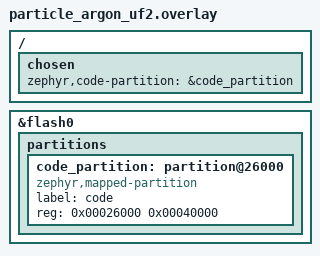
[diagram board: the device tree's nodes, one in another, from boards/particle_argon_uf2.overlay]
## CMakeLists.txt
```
cmake_minimum_required(VERSION 3.20.0)
find_package(Zephyr REQUIRED HINTS $ENV{ZEPHYR_BASE})
project(blank_app)

target_sources(app PRIVATE src/main.c)
```

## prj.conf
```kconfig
# blank_app - the minimal starting point for your own firmware on either
# board, with no dependency on Arduino IDE, no dependency on the mesh
# project, and no dependency on the ESP32 passthrough. This is what "raw
# Zephyr on this hardware" looks like at its smallest - copy this folder
# to start a real project.

CONFIG_GPIO=y

# --- Native USB-CDC console --------------------------------------------
# Same pattern as xenon_sensor/argon_gateway (see their own prj.conf/
# overlay comments for the full writeup): both boards' upstream devicetree
# defaults zephyr,console to &uart0, a header pin nothing is physically
# wired to on this project's bench setup - repointed to USB-CDC-ACM here
# via each board's own overlay instead, so printk/LOG output reaches a
# host over the same USB cable used for flashing and power.
CONFIG_LOG=y
CONFIG_CONSOLE=y
CONFIG_UART_CONSOLE=y
CONFIG_STDOUT_CONSOLE=y
CONFIG_USB_DEVICE_STACK_NEXT=y
CONFIG_CDC_ACM_SERIAL_INITIALIZE_AT_BOOT=y
CONFIG_CDC_ACM_SERIAL_PRODUCT_STRING="Blank App Console"
```

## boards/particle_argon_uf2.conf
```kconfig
# blank_app EXTRA Kconfig fragment - UF2/bootloader-safe build variant.
#
# Companion to boards/particle_argon_uf2.overlay, applied together via
# -DEXTRA_CONF_FILE alongside -DEXTRA_DTC_OVERLAY_FILE. The devicetree
# overlay alone is NOT enough to relocate the link address: Zephyr only
# links the app into its devicetree zephyr,code-partition when
# CONFIG_USE_DT_CODE_PARTITION is on, and that Kconfig option defaults to
# off on this SoC (confirmed by inspecting the plain overlay-only build's
# own .config and generated zephyr.hex, which still start at 0x0 even
# with the code_partition node present - and by reproducing the same
# default-off behavior on Zephyr's own upstream reference board for this
# exact scenario, adafruit_feather_nrf52840/nrf52840/uf2). Without this,
# the overlay's new partition would sit unused in the devicetree and the
# build would silently keep linking at 0x0 - exactly the failure mode
# Bug 1 is about, just moved one layer deeper.
CONFIG_USE_DT_CODE_PARTITION=y
```

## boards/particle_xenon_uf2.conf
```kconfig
# blank_app EXTRA Kconfig fragment - UF2/bootloader-safe build variant.
#
# Companion to boards/particle_xenon_uf2.overlay, applied together via
# -DEXTRA_CONF_FILE alongside -DEXTRA_DTC_OVERLAY_FILE. The devicetree
# overlay alone is NOT enough to relocate the link address: Zephyr only
# links the app into its devicetree zephyr,code-partition when
# CONFIG_USE_DT_CODE_PARTITION is on, and that Kconfig option defaults to
# off on this SoC (confirmed by inspecting the plain overlay-only build's
# own .config and generated zephyr.hex, which still start at 0x0 even
# with the code_partition node present - and by reproducing the same
# default-off behavior on Zephyr's own upstream reference board for this
# exact scenario, adafruit_feather_nrf52840/nrf52840/uf2). Without this,
# the overlay's new partition would sit unused in the devicetree and the
# build would silently keep linking at 0x0 - exactly the failure mode
# Bug 1 is about, just moved one layer deeper.
CONFIG_USE_DT_CODE_PARTITION=y
```

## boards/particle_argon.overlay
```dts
/*
 * blank_app board overlay - particle_argon
 *
 * Repoints the console to USB-CDC-ACM - same fix already applied and
 * verified on real hardware for argon_gateway/xenon_sensor/esp32_passthrough
 * (see their own overlays). Nothing else needs adding: led1 (the red
 * status LED) is already declared as a devicetree alias in the shared
 * mesh_feather.dtsi this board includes.
 */

/ {
	chosen {
		zephyr,console = &cdc_acm_uart0;
	};
};

&zephyr_udc0 {
	cdc_acm_uart0: cdc_acm_uart0 {
		compatible = "zephyr,cdc-acm-uart";
	};
};
```

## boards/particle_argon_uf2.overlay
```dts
/*
 * blank_app EXTRA overlay - UF2/bootloader-safe build variant.
 *
 * Applied ON TOP OF the board's own particle_argon.overlay /
 * particle_xenon.overlay (via -DEXTRA_DTC_OVERLAY_FILE), producing a
 * SEPARATE build meant for installing via UF2 drag-and-drop onto a board
 * that already has Adafruit's nRF52 bootloader + SoftDevice S140 - NOT
 * for direct SWD mass-erase flashing (that's what the plain per-board
 * overlay, unmodified by this file, remains for).
 *
 * The default board devicetree links application code at flash address
 * 0x0 - correct for a bare chip with no bootloader, wrong once a
 * bootloader/SoftDevice already occupies that address range: writing a
 * 0x0-linked image through UF2 corrupts the bootloader's own territory
 * and nothing valid ever boots (confirmed on real hardware this session -
 * see this project's SDD ledger, Argon UF2 round-trip task).
 *
 * 0x26000 is the same flash offset this project's own Arduino-sketch
 * SWD-flashing tooling already relies on for code living above
 * SoftDevice S140 and below the bootloader. 0x40000 (256KB) is a
 * deliberately conservative partition size for a small template app -
 * far below any real bootloader location near the top of the 1MB flash.
 *
 * Partition-conflict note: the board's default devicetree (via
 * mesh_feather.dtsi -> <nordic/nrf52840_partition.dtsi>) already defines
 * slot0_partition spanning 0xc000-0x82000, which fully contains our
 * 0x26000-0x66000 window - a real, physically-overlapping conflict, not
 * a hypothetical one. It's an MCUboot slot this app has no use for (this
 * app doesn't use MCUboot), so it's deleted below to clear the range.
 * Zephyr's own upstream partition layout for this exact scenario -
 * dts/vendor/nordic/nrf52840_partition_uf2_sdv6.dtsi, used by the real
 * Adafruit Feather nRF52840 UF2 board target - uses the same
 * "zephyr,mapped-partition" compatible for its application partition,
 * so that's what's used here too rather than the older
 * "fixed-partitions" style (which the board's existing partitions node
 * doesn't use in the first place).
 */

/delete-node/ &slot0_partition;

&flash0 {
	partitions {
		code_partition: partition@26000 {
			compatible = "zephyr,mapped-partition";
			label = "code";
			reg = <0x00026000 0x00040000>;
		};
	};
};

/ {
	chosen {
		zephyr,code-partition = &code_partition;
	};
};
```

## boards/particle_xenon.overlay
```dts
/*
 * blank_app board overlay - particle_xenon
 *
 * Same USB-CDC-ACM console fix as boards/particle_argon.overlay - see
 * that file's comment for the full writeup.
 */

/ {
	chosen {
		zephyr,console = &cdc_acm_uart0;
	};
};

&zephyr_udc0 {
	cdc_acm_uart0: cdc_acm_uart0 {
		compatible = "zephyr,cdc-acm-uart";
	};
};
```

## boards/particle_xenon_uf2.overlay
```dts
/*
 * blank_app EXTRA overlay - UF2/bootloader-safe build variant.
 *
 * Applied ON TOP OF the board's own particle_xenon.overlay (via
 * -DEXTRA_DTC_OVERLAY_FILE), producing a
 * SEPARATE build meant for installing via UF2 drag-and-drop onto a board
 * that already has Adafruit's nRF52 bootloader + SoftDevice S140 - NOT
 * for direct SWD mass-erase flashing (that's what the plain per-board
 * overlay, unmodified by this file, remains for).
 *
 * The default board devicetree links application code at flash address
 * 0x0 - correct for a bare chip with no bootloader, wrong once a
 * bootloader/SoftDevice already occupies that address range: writing a
 * 0x0-linked image through UF2 corrupts the bootloader's own territory
 * and nothing valid ever boots (confirmed on real hardware this session -
 * see this project's SDD ledger, Argon UF2 round-trip task).
 *
 * 0x26000 is the same flash offset this project's own Arduino-sketch
 * SWD-flashing tooling already relies on for code living above
 * SoftDevice S140 and below the bootloader. 0x40000 (256KB) is a
 * deliberately conservative partition size for a small template app -
 * far below any real bootloader location near the top of the 1MB flash.
 *
 * Partition-conflict note: the board's default devicetree (via
 * mesh_feather.dtsi -> <nordic/nrf52840_partition.dtsi>) already defines
 * slot0_partition spanning 0xc000-0x82000, which fully contains our
 * 0x26000-0x66000 window - a real, physically-overlapping conflict, not
 * a hypothetical one. It's an MCUboot slot this app has no use for (this
 * app doesn't use MCUboot), so it's deleted below to clear the range.
 * Zephyr's own upstream partition layout for this exact scenario -
 * dts/vendor/nordic/nrf52840_partition_uf2_sdv6.dtsi, used by the real
 * Adafruit Feather nRF52840 UF2 board target - uses the same
 * "zephyr,mapped-partition" compatible for its application partition,
 * so that's what's used here too rather than the older
 * "fixed-partitions" style (which the board's existing partitions node
 * doesn't use in the first place).
 */

/delete-node/ &slot0_partition;

&flash0 {
	partitions {
		code_partition: partition@26000 {
			compatible = "zephyr,mapped-partition";
			label = "code";
			reg = <0x00026000 0x00040000>;
		};
	};
};

/ {
	chosen {
		zephyr,code-partition = &code_partition;
	};
};
```

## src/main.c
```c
/*
 * blank_app - the minimal starting point for your own firmware on either
 * board. Blinks the red status LED (led1 - NOT led0, which is a known
 * "doesn't visibly light" pin documented elsewhere in this repo) and
 * prints a heartbeat over USB-CDC once a second, so you have a known-good
 * starting point that's easy to confirm is actually running before you
 * start replacing this file with your own project.
 *
 * SPDX-License-Identifier: Apache-2.0
 */

#include <zephyr/kernel.h>
#include <zephyr/device.h>
#include <zephyr/drivers/gpio.h>
#include <zephyr/logging/log.h>

LOG_MODULE_REGISTER(blank_app, LOG_LEVEL_INF);

static const struct gpio_dt_spec led = GPIO_DT_SPEC_GET(DT_ALIAS(led1), gpios);

int main(void)
{
	int err;
	uint32_t count = 0;

	if (!gpio_is_ready_dt(&led)) {
		LOG_ERR("LED device not ready");
		return -ENODEV;
	}

	err = gpio_pin_configure_dt(&led, GPIO_OUTPUT_INACTIVE);
	if (err) {
		LOG_ERR("Failed to configure LED (err %d)", err);
		return err;
	}

	LOG_INF("blank_app ready - this is the minimal starting point");

	while (1) {
		gpio_pin_toggle_dt(&led);
		LOG_INF("heartbeat %u", count++);
		k_sleep(K_SECONDS(1));
	}

	return 0;
}
```
